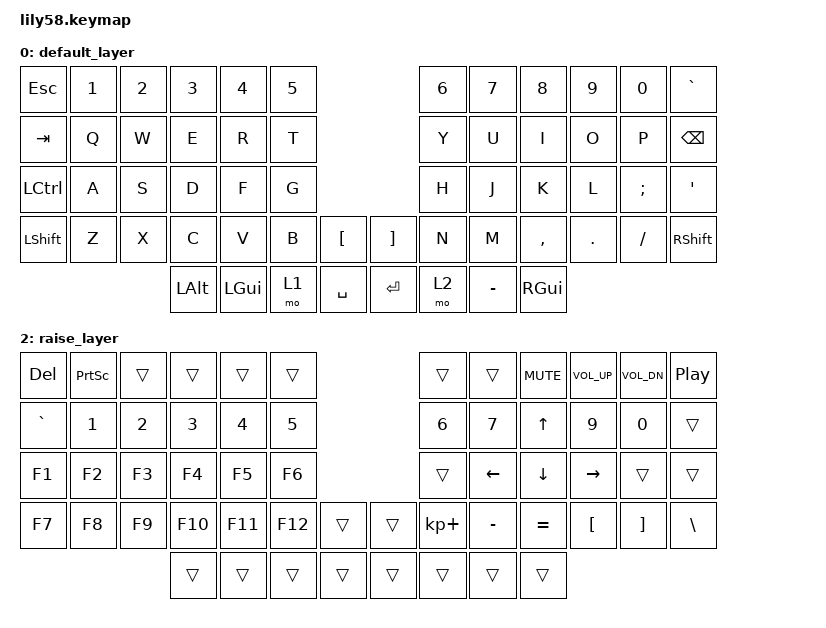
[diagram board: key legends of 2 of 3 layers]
/*
 * Copyright (c) 2020 The ZMK Contributors
 *
 * SPDX-License-Identifier: MIT
 */

#include <behaviors.dtsi>
#include <dt-bindings/zmk/keys.h>
#include <dt-bindings/zmk/bt.h>
#include <dt-bindings/zmk/ext_power.h>

/ {
		macros {
        tmux: tmux{
            compatible = "zmk,behavior-macro";
            #binding-cells = <0>;
            bindings = <&sk LCTRL &kp A>;
            label = "TMUX";
        };
        tmuxone: tmuxone{
            compatible = "zmk,behavior-macro";
            #binding-cells = <0>;
            bindings = <&sk LCTRL &kp A &kp N1>;
            label = "TMUXONE";
        };
        tmuxtwo: tmuxtwo{
            compatible = "zmk,behavior-macro";
            #binding-cells = <0>;
            bindings = <&sk LCTRL &kp A &kp N2>;
            label = "TMUXTWO";
        };
        tmuxthree: tmuxthree{
            compatible = "zmk,behavior-macro";
            #binding-cells = <0>;
            bindings = <&sk LCTRL &kp A &kp N3>;
            label = "TMUXTHREE";
        };
        tmuxfour: tmuxfour{
            compatible = "zmk,behavior-macro";
            #binding-cells = <0>;
            bindings = <&sk LCTRL &kp A &kp N4>;
            label = "TMUXFOUR";
        };
        tmuxfive: tmuxfive{
            compatible = "zmk,behavior-macro";
            #binding-cells = <0>;
            bindings = <&sk LCTRL &kp A &kp N5>;
            label = "TMUXFIVE";
        };
    };

    keymap {
        compatible = "zmk,keymap";

        default_layer {
// ------------------------------------------------------------------------------------------------------------
// |  ESC  |  1  |  2  |  3   |  4   |  5   |                   |  6   |  7    |  8    |  9   |   0   |   `   |
// |  TAB  |  Q  |  W  |  E   |  R   |  T   |                   |  Y   |  U    |  I    |  O   |   P   | BSPC  |
// |  CTRL |  A  |  S  |  D   |  F   |  G   |                   |  H   |  J    |  K    |  L   |   ;   |   '   |
// | SHIFT |  Z  |  X  |  C   |  V   |  B   |   "["  |  |  "]"  |  N   |  M    |  ,    |  .   |   /   | SHIFT |
//                     | ALT  | GUI  | LOWER|  SPACE |  | ENTER | RAISE|  -    | GUI   |
            bindings = <
&kp ESC   &kp N1 &kp N2 &kp N3   &kp N4   &kp N5                     &kp N6 &kp N7   &kp N8    &kp N9  &kp N0   &kp GRAVE
&kp TAB   &kp Q  &kp W  &kp E    &kp R    &kp T                      &kp Y  &kp U    &kp I     &kp O   &kp P    &kp BSPC 
&kp LCTRL &kp A  &kp S  &kp D    &kp F    &kp G                      &kp H  &kp J    &kp K     &kp L   &kp SEMI &kp SQT
&kp LSHFT &kp Z  &kp X  &kp C    &kp V    &kp B  &kp LBKT   &kp RBKT &kp N  &kp M    &kp COMMA &kp DOT &kp FSLH &kp RSHFT
                        &kp LALT &kp LGUI &mo 1  &kp SPACE  &kp RET  &mo 2  &kp MINUS &kp RGUI
            >;

            sensor-bindings = <&inc_dec_kp C_VOL_UP C_VOL_DN>;
        };

        lower_layer {
// ------------------------------------------------------------------------------------------------------------
// |  tmux |tmux1|tmux2|tmux3 |tmux4 |tmux5 |                   |      |       |       |      |       |       |
// |  F1   |  F2 |  F3 |  F4  |  F5  |  F6  |                   |  F7  |  F8   |  F9   |  F10 |  F11  |  F12  |
// |   `   |  !  |  @  |  #   |  $   |  %   |                   |  ^   |  &    |  *    |  (   |   )   |   ~   |
// | BTCLR | BT1 | BT2 | BT3  |      |      |        |  |       |      |  _    |  +    |  {   |   }   |  "|"  |
//                     |      |      |      |        |  |       |      |       |       |
            bindings = <
&tmux      &tmuxone         &tmuxtwo          &tmuxthree 				&tmuxfour    &tmuxfive                    &trans    &trans    &trans    &trans    &trans    &trans
&kp F1     &kp F2           &kp F3            &kp F4            &kp F5       &kp F6                       &kp F7    &kp F8    &kp F9    &kp F10   &kp F11   &kp F12
&kp GRAVE  &kp EXCL         &kp AT            &kp HASH          &kp DOLLAR   &kp PRCNT                    &kp CARET &kp AMPS  &kp ASTRK &kp LPAR  &kp RPAR  &kp TILDE
&bt BT_CLR &bt BT_SEL 0     &bt BT_SEL 1      &bt BT_SEL 2      &trans       &trans   &trans    &trans    &kp MINUS &kp PLUS  &kp LBRC  &kp RBRC  &kp PIPE
                                              &trans            &trans       &trans    &trans   &trans    &trans    &trans    &trans
            >;

            sensor-bindings = <&inc_dec_kp C_VOL_UP C_VOL_DN>;
        };

        raise_layer {
// ------------------------------------------------------------------------------------------------------------
// |  DEL  |PSCRN|     |      |      |      |                   |      |       | MUTE  |VOL_UP|VOL_DWN|PL/PSE |
// |   `   |  1  |  2  |  3   |  4   |  5   |                   |  6   |   7   |   ^   |  9   |   0   |       |
// |   F1  |  F2 |  F3 |  F4  |  F5  |  F6  |                   |      |   <-  |   v   |  ->  |       |       |
// |   F7  |  F8 |  F9 |  F10 |  F11 |  F12 |        |  |       |  +   |   -   |   =   |  [   |   ]   |   \   |
//                     |      |      |      |        |  |       |      |       |       |
            bindings = <
&kp DEL   &kp PSCRN &trans &trans  &trans  &trans                    &trans      &trans    &kp C_MUTE &kp C_VOL_UP &kp C_VOL_DN &kp C_PLAY_PAUSE
&kp GRAVE &kp N1 &kp N2 &kp N3  &kp N4  &kp N5                       &kp N6      &kp N7    &kp UP    &kp N9   &kp N0    &trans
&kp F1    &kp F2 &kp F3 &kp F4  &kp F5  &kp F6                       &trans      &kp LEFT  &kp DOWN  &kp RIGHT &trans   &trans
&kp F7    &kp F8 &kp F9 &kp F10 &kp F11 &kp F12   &trans   &trans    &kp KP_PLUS &kp MINUS &kp EQUAL &kp LBKT &kp RBKT  &kp BSLH
                        &trans  &trans  &trans    &trans   &trans    &trans      &trans    &trans
            >;

            sensor-bindings = <&inc_dec_kp C_VOL_UP C_VOL_DN>;
        };
    };
};
